AUTOSAR XML (schema 00050)
package /ComponentTypes
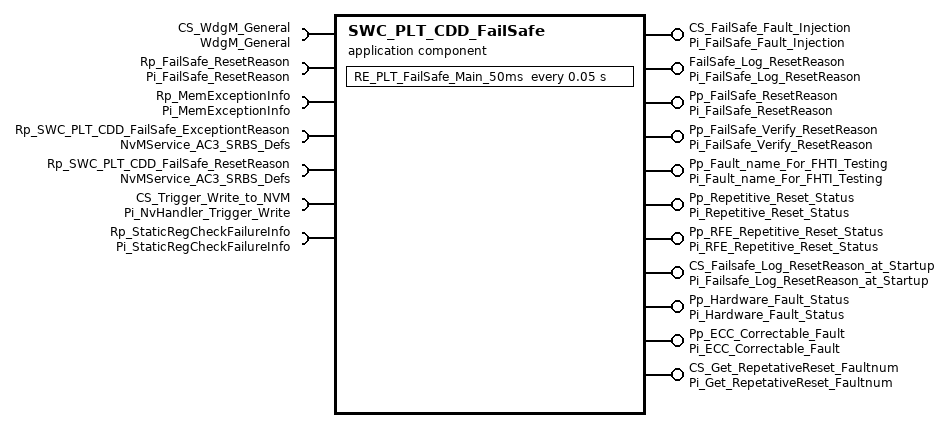
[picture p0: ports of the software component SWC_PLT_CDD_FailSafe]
  application sw component type SWC_PLT_CDD_FailSafe  # SWC for fail safe concept implementation.
    7 x provide port:
      CS_FailSafe_Fault_Injection: server-com-spec{operation=Read, queue-length=1}, provided-interface=Pi_FailSafe_Fault_Injection
      FailSafe_Log_ResetReason: server-com-spec{operation=FailSafe_Log_ResetReason, queue-length=1}, provided-interface=Pi_FailSafe_Log_ResetReason
      Pp_FailSafe_ResetReason: nonqueued-sender-com-spec{data-element=De_FailSafe_ResetReason, init-value=constant-reference=C_FailSafe_ResetReason_T}, provided-interface=Pi_FailSafe_ResetReason
      Pp_FailSafe_Verify_ResetReason: nonqueued-sender-com-spec{data-element=FailSafe_Verify_ResetReason, init-value=0}, provided-interface=Pi_FailSafe_Verify_ResetReason
      Pp_Fault_name_For_FHTI_Testing: nonqueued-sender-com-spec{data-element=De_Fault_name_FHTI, init-value=0}, provided-interface=Pi_Fault_name_For_FHTI_Testing
      Pp_Repetitive_Reset_Status: nonqueued-sender-com-spec{data-element=De_Repetitive_Reset_Status, init-value=85}, provided-interface=Pi_Repetitive_Reset_Status
      Pp_RFE_Repetitive_Reset_Status: nonqueued-sender-com-spec{data-element=De_RFE_Repetitive_Reset_Status, init-value=0}, provided-interface=Pi_RFE_Repetitive_Reset_Status
    7 x require port:
      CS_WdgM_General: required-interface=WdgM_General
        required-com-specs:
          ActivateSupervisionEntity
          DeactivateSupervisionEntity
          GetFirstExpiredSEID
          GetGlobalStatus
          GetLocalStatus
          GetMode
          PerformReset
          SetMode
      Rp_FailSafe_ResetReason: nonqueued-receiver-com-spec{data-element=De_FailSafe_ResetReason, filter=data-filter-type=ALWAYS, init-value=constant-reference=C_FailSafe_ResetReason_T}, required-interface=Pi_FailSafe_ResetReason
      Rp_MemExceptionInfo: nonqueued-receiver-com-spec{data-element=De_MemExceptionInfo, filter=data-filter-type=ALWAYS, init-value=constant-reference=C_MemExceptionInfo}, required-interface=Pi_MemExceptionInfo
      Rp_SWC_PLT_CDD_FailSafe_ExceptiontReason: required-com-specs=[EraseBlock, GetErrorStatus, InvalidateNvBlock, ReadBlock, RestoreBlockDefaults, SetRamBlockStatus, WriteBlock], required-interface=NvMService_AC3_SRBS_Defs
      Rp_SWC_PLT_CDD_FailSafe_ResetReason: required-com-specs=[EraseBlock, GetErrorStatus, InvalidateNvBlock, ReadBlock, RestoreBlockDefaults, SetRamBlockStatus, WriteBlock], required-interface=NvMService_AC3_SRBS_Defs
      CS_Trigger_Write_to_NVM: client-com-spec=NvHandler_Trigger_Write_To_NVM, required-interface=Pi_NvHandler_Trigger_Write
      Rp_StaticRegCheckFailureInfo: nonqueued-receiver-com-spec{data-element=De_StaticRegCheckFailureInfo, filter=data-filter-type=ALWAYS, init-value=35 x 0}, required-interface=Pi_StaticRegCheckFailureInfo
    4 x provide port:
      CS_Failsafe_Log_ResetReason_at_Startup: server-com-spec{operation=fcru_reset_reason, queue-length=1}, provided-interface=Pi_Failsafe_Log_ResetReason_at_Startup
      Pp_Hardware_Fault_Status: nonqueued-sender-com-spec{data-element=De_Hardware_Fault_Status, init-value=fields=RA_Fault_Status:0}, provided-interface=Pi_Hardware_Fault_Status
      Pp_ECC_Correctable_Fault: nonqueued-sender-com-spec{data-element=De_ECC_Correctable_Fault, init-value=fields=[aa_mem_sec:0, artie_mem_sec:0, csi2_sec:0, dsp_opif_sec:0, dsp_idma_sec:0, dsp_iram_sec_axis:0, dsp_dcache_sec:0, dsp_dram_sec:0, dsp_icache_sec:0, dsp_iram_sec:0, ra_cqmem_sec:0, ra_dpmem_sec:0, ra_estmem_sec:0, ra_idxmem_sec:0, ra_phmem_sec:0, ra_wcmem_sec:0, sp_axi_m_corr:0, sp_axi_s_corr:0, sysmem0_sec:0, sysmem1_sec:0, not_recorded:0]}, provided-interface=Pi_ECC_Correctable_Fault
      CS_Get_RepetativeReset_Faultnum: server-com-spec{operation=Operation, queue-length=1}, provided-interface=Pi_Get_RepetativeReset_Faultnum
    behavior SWC_PLT_CDD_FailSafe_InternalBehavior: handle-termination-and-restart=NO-SUPPORT
      ar-typed-per-instance-memorys:
        data ExceptionReason_PIM: sw-calibration-access=READ-WRITE, type=Dt_FailSafe_ExceptionReason_T
      operation invoked event OIT_CS_FailSafe_Fault_Injection_Read_CS_FailSafe_Fault_Injection_Read: start-on-event=CS_FailSafe_Fault_Injection, operation=CS_FailSafe_Fault_Injection.Read
      operation invoked event OIT_FailSafe_Log_ResetReason_FailSafe_Log_ResetReason_FailSafe_Log_ResetReason_FailSafe_Log_ResetReason: start-on-event=FailSafe_Log_ResetReason, operation=FailSafe_Log_ResetReason.FailSafe_Log_ResetReason
      init event SWC_PLT_CDD_FailSafe_InitEvent: start-on-event=RE_PLT_FailSafe_Init
      timing event TMT_RE_FailSafe_Main_50ms: start-on-event=RE_PLT_FailSafe_Main_50ms, period=0.05
      operation invoked event OIT_CS_Failsafe_Log_ResetReason_at_Startup_CS_Failsafe_Log_ResetReason_at_Startup_fcru_reset_reason: start-on-event=CS_Failsafe_Log_ResetReason_at_Startup, operation=CS_Failsafe_Log_ResetReason_at_Startup.fcru_reset_reason
      operation invoked event OIT_CS_Get_RepetativeReset_Faultnum_Operation_CS_Get_RepetativeReset_Faultnum_Operation: start-on-event=CS_Get_RepetativeReset_Faultnum_Operation, operation=CS_Get_RepetativeReset_Faultnum.Operation
      per-instance-parameters:
        parameter data prototype ExceptionReason_DefaultValue: sw-calibration-access=READ-WRITE, type=Dt_FailSafe_ExceptionReason_T, init-value=constant-reference=C_FailSafe_ExceptionReason_T
        parameter data prototype ResetReason_DefaultValue: sw-calibration-access=READ-WRITE, type=Dt_FailSafe_ResetReason_T, init-value=constant-reference=C_FailSafe_ResetReason_T
      6 x runnable:
        CS_FailSafe_Fault_Injection
        FailSafe_Log_ResetReason: can-be-invoked-concurrently=true
          sync call SC_CS_WdgM_General_GetFirstExpiredSEID: operation=CS_WdgM_General.GetFirstExpiredSEID
          sync call SC_CS_Trigger_Write_to_NVM_NvHandler_Trigger_Write_To_NVM: operation=CS_Trigger_Write_to_NVM.NvHandler_Trigger_Write_To_NVM
        RE_PLT_FailSafe_Init  # Init runnable for Failsafe module.
          data-receive-point-by-arguments:
            access REC_Rp_FailSafe_ResetReason_1_De_FailSafe_ResetReason: accessed-variable=Rp_FailSafe_ResetReason.De_FailSafe_ResetReason
          data-send-points:
            4 x access:
              SEND_Pp_FailSafe_ResetReason_De_FailSafe_ResetReason: accessed-variable=Pp_FailSafe_ResetReason.De_FailSafe_ResetReason
              SEND_Pp_FailSafe_Verify_ResetReason_FailSafe_Verify_ResetReason: accessed-variable=Pp_FailSafe_Verify_ResetReason.FailSafe_Verify_ResetReason
              SEND_Pp_Repetitive_Reset_Status_De_Repetitive_Reset_Status: accessed-variable=Pp_Repetitive_Reset_Status.De_Repetitive_Reset_Status
              SEND_Pp_RFE_Repetitive_Reset_Status_De_RFE_Repetitive_Reset_Status: accessed-variable=Pp_RFE_Repetitive_Reset_Status.De_RFE_Repetitive_Reset_Status
        RE_PLT_FailSafe_Main_50ms  # 50 ms runnable for fail safe module.
          data-receive-point-by-arguments:
            access REC_Rp_MemExceptionInfo_De_MemExceptionInfo: accessed-variable=Rp_MemExceptionInfo.De_MemExceptionInfo
            access REC_Rp_StaticRegCheckFailureInfo_De_StaticRegCheckFailureInfo: accessed-variable=Rp_StaticRegCheckFailureInfo.De_StaticRegCheckFailureInfo
          data-send-points:
            access SEND_Pp_Fault_name_For_FHTI_Testing_De_Fault_name_FHTI: accessed-variable=Pp_Fault_name_For_FHTI_Testing.De_Fault_name_FHTI
            access SEND_Pp_Hardware_Fault_Status_De_Hardware_Fault_Status: accessed-variable=Pp_Hardware_Fault_Status.De_Hardware_Fault_Status
            access SEND_Pp_ECC_Correctable_Fault_De_ECC_Correctable_Fault: accessed-variable=Pp_ECC_Correctable_Fault.De_ECC_Correctable_Fault
          5 x sync call:
            SC_Rp_SWC_PLT_CDD_FailSafe_ExceptiontReason_GetErrorStatus: operation=Rp_SWC_PLT_CDD_FailSafe_ExceptiontReason.GetErrorStatus
            SC_Rp_SWC_PLT_CDD_FailSafe_ExceptiontReason_WriteBlock: operation=Rp_SWC_PLT_CDD_FailSafe_ExceptiontReason.WriteBlock
            SC_Rp_SWC_PLT_CDD_FailSafe_ResetReason_GetErrorStatus: operation=Rp_SWC_PLT_CDD_FailSafe_ResetReason.GetErrorStatus
            SC_Rp_SWC_PLT_CDD_FailSafe_ResetReason_ReadBlock: operation=Rp_SWC_PLT_CDD_FailSafe_ResetReason.ReadBlock
            SC_Rp_SWC_PLT_CDD_FailSafe_ResetReason_WriteBlock: operation=Rp_SWC_PLT_CDD_FailSafe_ResetReason.WriteBlock
        CS_Failsafe_Log_ResetReason_at_Startup
        CS_Get_RepetativeReset_Faultnum_Operation
  swc implementation SWC_PLT_CDD_FailSafe_Implementation: behavior=SWC_PLT_CDD_FailSafe_InternalBehavior
    code-descriptors:
      code Default: artifact-descriptors=autosar-engineering-object=category=SWSRC
